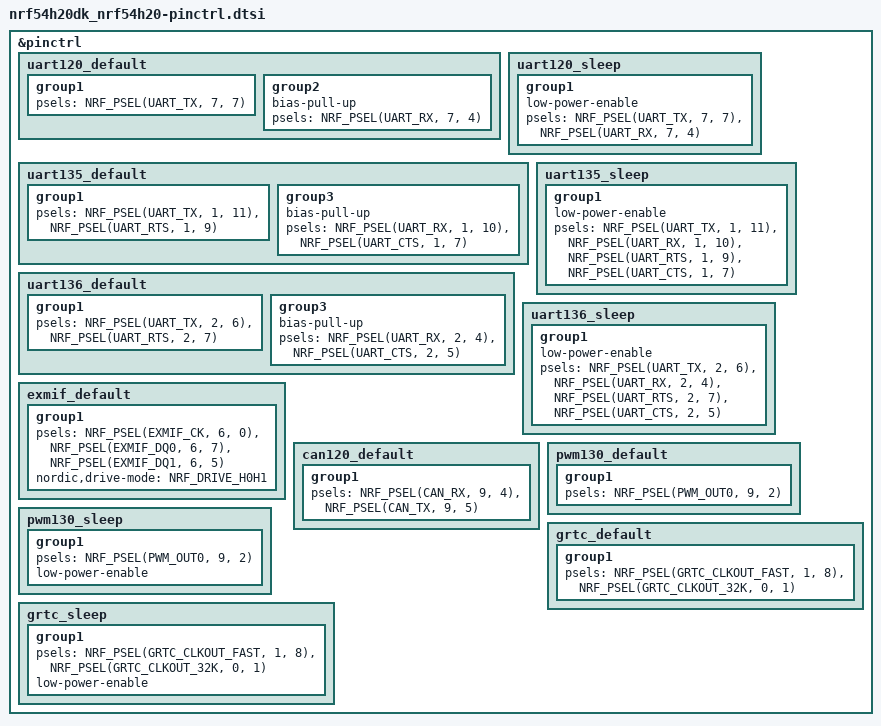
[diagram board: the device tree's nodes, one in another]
/*
 * Copyright (c) 2024 Nordic Semiconductor ASA
 *
 * SPDX-License-Identifier: Apache-2.0
 */

&pinctrl {
	/omit-if-no-ref/ uart120_default: uart120_default {
		group1 {
			psels = <NRF_PSEL(UART_TX, 7, 7)>;
		};

		group2 {
			bias-pull-up;
			psels = <NRF_PSEL(UART_RX, 7, 4)>;
		};
	};

	/omit-if-no-ref/ uart120_sleep: uart120_sleep {
		group1 {
			low-power-enable;
			psels = <NRF_PSEL(UART_TX, 7, 7)>,
				<NRF_PSEL(UART_RX, 7, 4)>;
		};
	};

	/omit-if-no-ref/ uart135_default: uart135_default {
		group1 {
			psels = <NRF_PSEL(UART_TX, 1, 11)>,
				<NRF_PSEL(UART_RTS, 1, 9)>;
		};

		group3 {
			bias-pull-up;
			psels = <NRF_PSEL(UART_RX, 1, 10)>,
				<NRF_PSEL(UART_CTS, 1, 7)>;
		};
	};

	/omit-if-no-ref/ uart135_sleep: uart135_sleep {
		group1 {
			low-power-enable;
			psels = <NRF_PSEL(UART_TX, 1, 11)>,
				<NRF_PSEL(UART_RX, 1, 10)>,
				<NRF_PSEL(UART_RTS, 1, 9)>,
				<NRF_PSEL(UART_CTS, 1, 7)>;
		};
	};

	/omit-if-no-ref/ uart136_default: uart136_default {
		group1 {
			psels = <NRF_PSEL(UART_TX, 2, 6)>,
				<NRF_PSEL(UART_RTS, 2, 7)>;
		};

		group3 {
			bias-pull-up;
			psels = <NRF_PSEL(UART_RX, 2, 4)>,
				<NRF_PSEL(UART_CTS, 2, 5)>;
		};
	};

	/omit-if-no-ref/ uart136_sleep: uart136_sleep {
		group1 {
			low-power-enable;
			psels = <NRF_PSEL(UART_TX, 2, 6)>,
				<NRF_PSEL(UART_RX, 2, 4)>,
				<NRF_PSEL(UART_RTS, 2, 7)>,
				<NRF_PSEL(UART_CTS, 2, 5)>;
		};
	};

	/omit-if-no-ref/ exmif_default: exmif_default {
		group1 {
			psels = <NRF_PSEL(EXMIF_CK, 6, 0)>,
				<NRF_PSEL(EXMIF_DQ0, 6, 7)>,
				<NRF_PSEL(EXMIF_DQ1, 6, 5)>;
			nordic,drive-mode = <NRF_DRIVE_H0H1>;
		};
	};

	/omit-if-no-ref/ can120_default: can120_default {
		group1 {
			psels = <NRF_PSEL(CAN_RX, 9, 4)>,
				<NRF_PSEL(CAN_TX, 9, 5)>;
		};
	};

	/omit-if-no-ref/ pwm130_default: pwm130_default {
		group1 {
			psels = <NRF_PSEL(PWM_OUT0, 9, 2)>;
		};
	};

	/omit-if-no-ref/ pwm130_sleep: pwm130_sleep {
		group1 {
			psels = <NRF_PSEL(PWM_OUT0, 9, 2)>;
			low-power-enable;
		};
	};

	/omit-if-no-ref/ grtc_default: grtc_default {
		group1 {
			psels = <NRF_PSEL(GRTC_CLKOUT_FAST, 1, 8)>,
				<NRF_PSEL(GRTC_CLKOUT_32K, 0, 1)>;
		};
	};

	/omit-if-no-ref/ grtc_sleep: grtc_sleep {
		group1 {
			psels = <NRF_PSEL(GRTC_CLKOUT_FAST, 1, 8)>,
				<NRF_PSEL(GRTC_CLKOUT_32K, 0, 1)>;
			low-power-enable;
		};
	};
};
